# MKM32Z5 register map
File version: 1.6
Registers are 8-bit, read-write, reset 0x0 unless marked. A register's access mark holds for its fields unless they carry their own. Offsets are from the block's base; [hi:lo] are bit positions; {n}, {i} and the like mark numbered series.

## DMAMUX0 — DMA channel multiplexor
Base 0x40021000; register names take the prefix DMAMUX0_
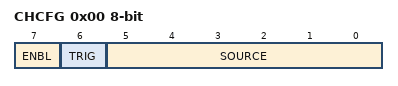
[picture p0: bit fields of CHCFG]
0x00 CHCFG — Channel Configuration register
  [7] ENBL — DMA Channel Enable
    0=DMA channel is disabled. This mode is primarily used during configuration of the DMAMux. The DMA has separate channel enables/disables, which should be used to disable or reconfigure a DMA channel.; 1=DMA channel is enabled
  [6] TRIG — DMA Channel Trigger Enable
    0=Triggering is disabled. If triggering is disabled and the ENBL bit is set, the DMA Channel will simply route the specified source to the DMA channel. (Normal mode); 1=Triggering is enabled. If triggering is enabled and the ENBL bit is set, the DMAMUX is in Periodic Trigger mode.
  [5:0] SOURCE — DMA Channel Source (Slot)

## DMAMUX1 — DMA channel multiplexor
Base 0x40022000; register names take the prefix DMAMUX1_
Registers as DMAMUX0.

## DMAMUX2 — DMA channel multiplexor
Base 0x40023000; register names take the prefix DMAMUX2_
Registers as DMAMUX0.

## DMAMUX3 — DMA channel multiplexor
Base 0x40024000; register names take the prefix DMAMUX3_
Registers as DMAMUX0.

## RNG — Random Number Generator Accelerator
Base 0x40029000; register names take the prefix RNG_
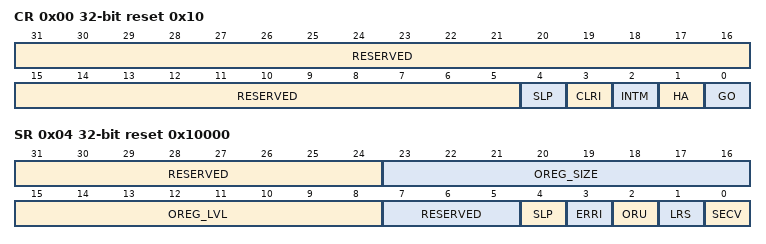
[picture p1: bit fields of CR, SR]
0x00 CR 32-bit reset 0x10 — RNGA Control Register
  [31:5] RESERVED ro
  [4] SLP — Sleep
    0=RNGA is not in Sleep mode; 1=RNGA is in Sleep mode
  [3] CLRI wo — Clear Interrupt
    0=Do not clear the interrupt; 1=Clear the interrupt
  [2] INTM — Interrupt Mask
    0=Interrupt is enabled; 1=Interrupt is masked
  [1] HA — High Assurance
    0=Notification of security violations is masked; 1=Notification of security violations is enabled
  [0] GO
    0=RNGA Output Register is not loaded with random data; 1=RNGA Output Register is loaded with random data
0x04 SR 32-bit ro reset 0x10000 — RNGA Status Register
  [31:24] RESERVED
  [23:16] OREG_SIZE — Output Register Size
  [15:8] OREG_LVL — Output Register Level
  [7:5] RESERVED
  [4] SLP — Sleep
    0=The RNGA is not in Sleep mode; 1=The RNGA is in Sleep mode
  [3] ERRI — Error Interrupt
    0=The RNGA Output Register has not been read while empty; 1=The RNGA Output Register has been read while empty
  [2] ORU — Output Register Underflow
    0=The RNGA Output Register has not been read while empty since last read of the RNGA Status Register; 1=The RNGA Output Register has been read while empty since last read of the RNGA Status Register
  [1] LRS — Last Read Status
    0=Last read was performed while the RNGA Output Register was not empty; 1=Last read was performed while the RNGA Output Register was empty (underflow condition)
  [0] SECV — Security Violation
    0=No security violations have occured or CR[HA] is not set; 1=A security violation has occurred
0x08 ER 32-bit wo — RNGA Entropy Register
  [31:0] EXT_ENT — External Entropy
0x0C OR 32-bit ro — RNGA Output Register
  [31:0] RANDOUT — Random Output

## PIT0 — Periodic Interrupt Timer
Base 0x4002D000; register names take the prefix PIT0_
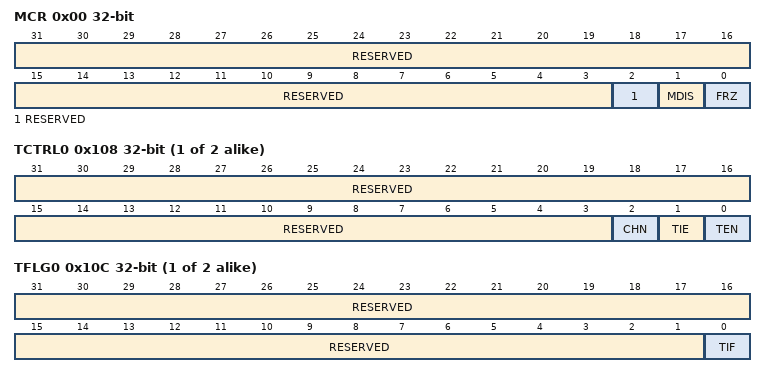
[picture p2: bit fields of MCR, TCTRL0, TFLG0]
0x00 MCR 32-bit — PIT Module Control Register
  [31:3] RESERVED ro
  [2] RESERVED ro
  [1] MDIS — Module Disable - (PIT section)
    0=Clock for standard PIT timers is enabled; 1=Clock for standard PIT timers is disabled
  [0] FRZ — Freeze
    0=Timers continue to run in Debug mode; 1=Timers are stopped in Debug mode
{0x100+0x10*i} LDVAL{i} (i=0..1) 32-bit — Timer Load Value Register
  [31:0] TSV — Timer Start Value
{0x104+0x10*i} CVAL{i} (i=0..1) 32-bit ro — Current Timer Value Register
  [31:0] TVL — Current Timer Value
{0x108+0x10*i} TCTRL{i} (i=0..1) 32-bit — Timer Control Register
  [31:3] RESERVED ro
  [2] CHN — Chain Mode
    0=Timer is not chained; 1=Timer is chained to previous timer. For example, for Channel 2, if this field is set, Timer 2 is chained to Timer 1.
  [1] TIE — Timer Interrupt Enable
    0=Interrupt requests from Timer n are disabled; 1=Interrupt will be requested whenever TIF is set
  [0] TEN — Timer Enable
    0=Timer n is disabled; 1=Timer n is enabled
{0x10C+0x10*i} TFLG{i} (i=0..1) 32-bit — Timer Flag Register
  [31:1] RESERVED ro
  [0] TIF — Timer Interrupt Flag
    0=Timeout has not yet occurred; 1=Timeout has occurred

## PIT1 — Periodic Interrupt Timer
Base 0x4002E000; register names take the prefix PIT1_
Registers as PIT0.
